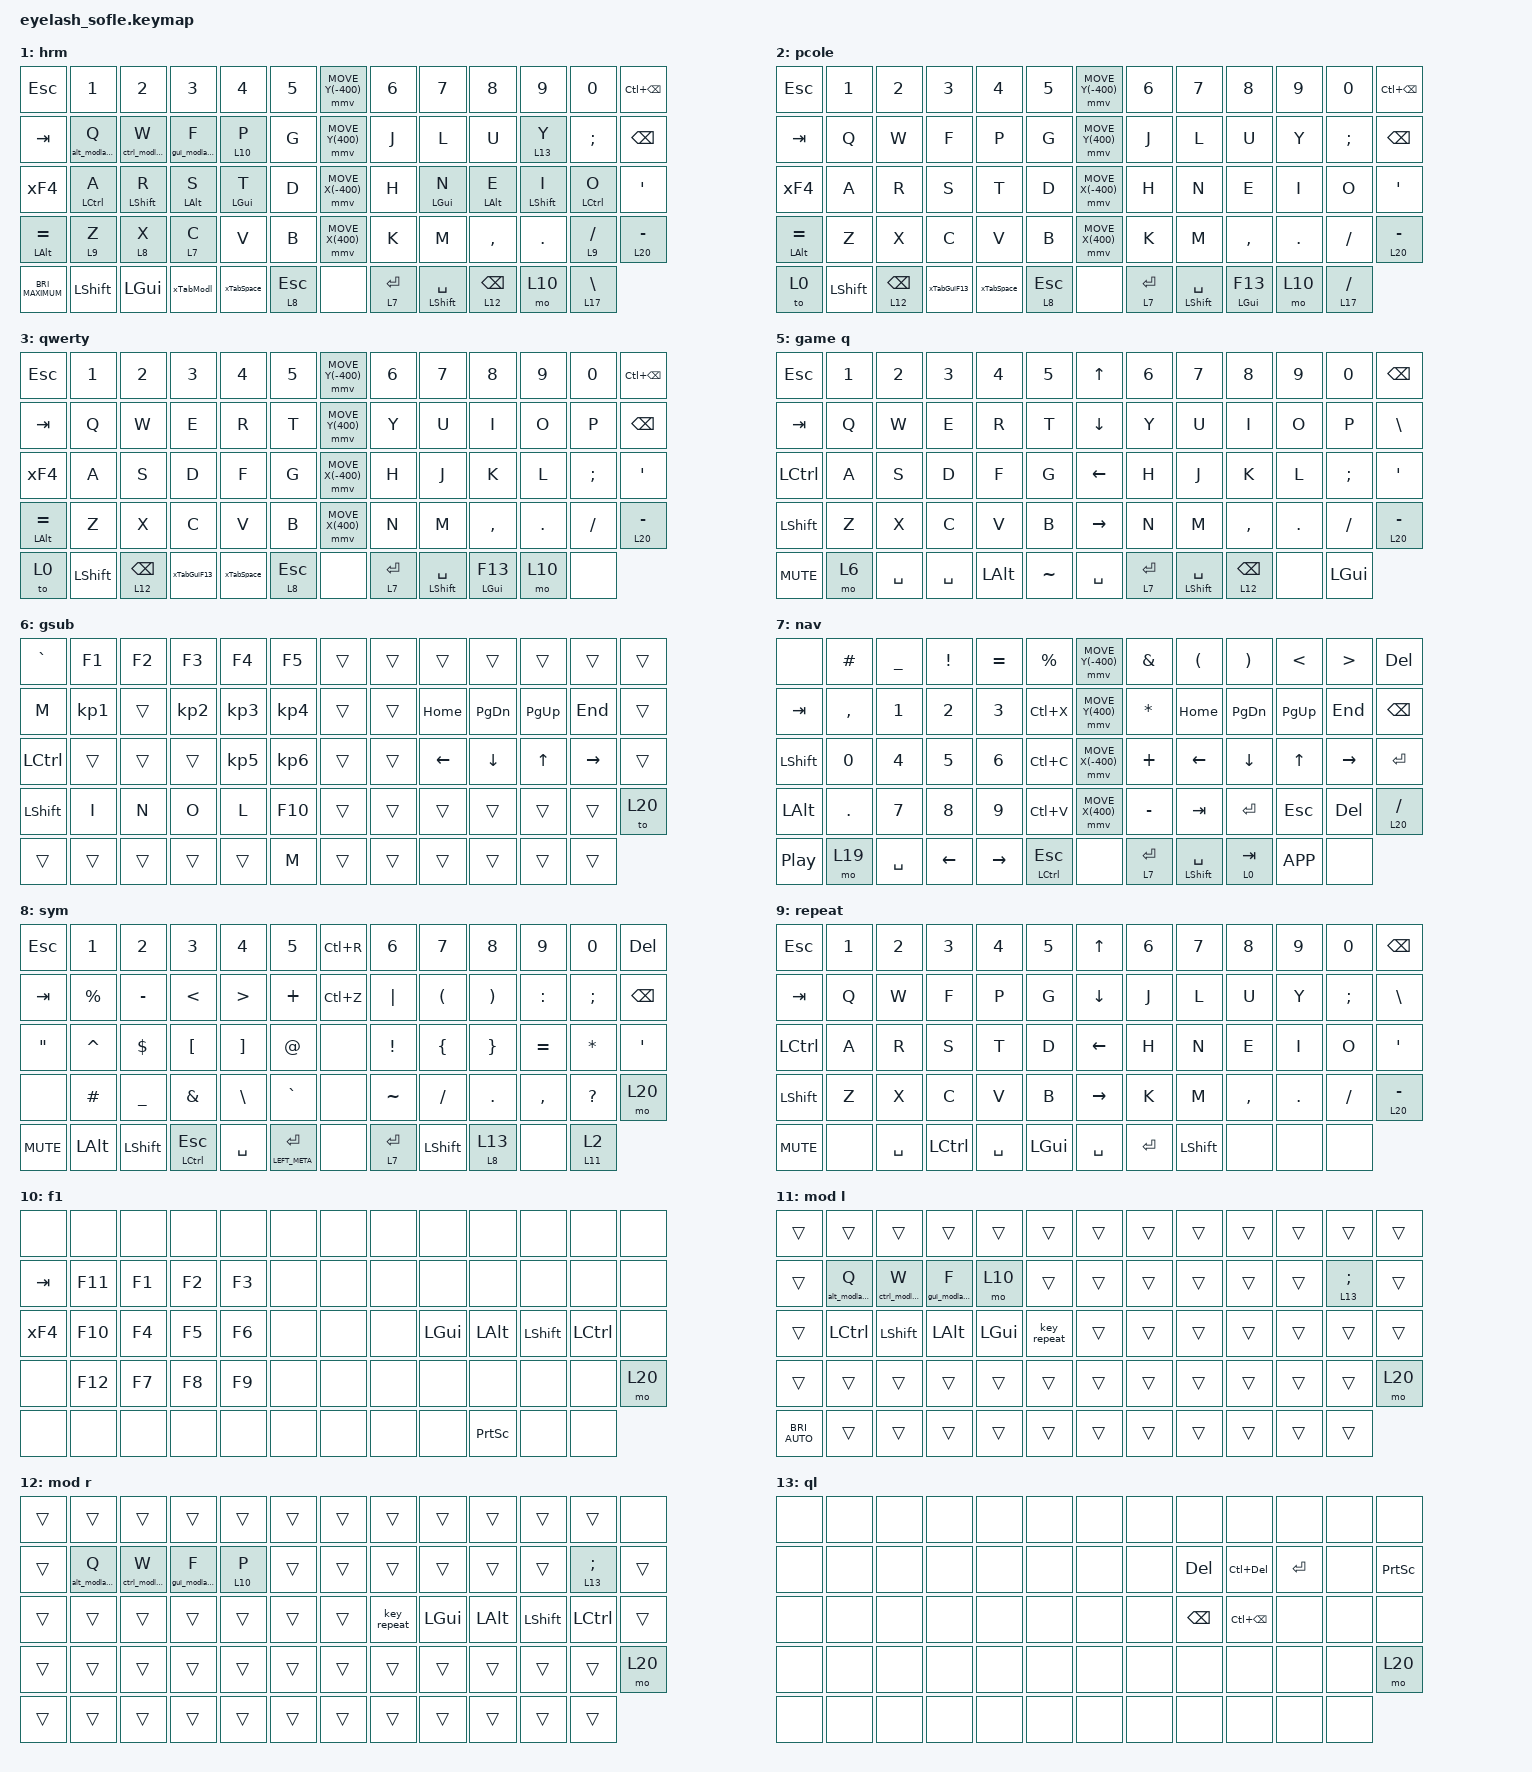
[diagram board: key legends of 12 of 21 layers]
#define ZMK_POINTING_DEFAULT_MOVE_VAL 1200  // 600
#define ZMK_POINTING_DEFAULT_SCRL_VAL 25   // 10

#include <input/processors.dtsi>
#include <zephyr/dt-bindings/input/input-event-codes.h>
#include <behaviors.dtsi>
#include <dt-bindings/zmk/backlight.h>
#include <dt-bindings/zmk/bt.h>
#include <dt-bindings/zmk/ext_power.h>
#include <dt-bindings/zmk/keys.h>
#include <dt-bindings/zmk/outputs.h>
#include <dt-bindings/zmk/pointing.h>
#include <dt-bindings/zmk/rgb.h>

&mmv_input_listener { input-processors = <&zip_xy_scaler 2 1>; };

&msc_input_listener { input-processors = <&zip_scroll_scaler 2 1>; };

&msc {
    acceleration-exponent = <1>;      // 0
    time-to-max-speed-ms = <100>;       // 300
    delay-ms = <0>;                   // 0
};

&mmv {
    time-to-max-speed-ms = <500>;
    acceleration-exponent = <1>;
    trigger-period-ms = <16>;
};

#define COMBO_SYM_SETTINGS_COMMON    \
    layers = <0 1 2 3>;    \
    timeout-ms = <15>;    \
    require-prior-idle-ms = <150>;
#define COMBO_MOD_SETTINGS_COMMON    \
    layers = <0 1 2 3>;    \
    timeout-ms = <15>;    \
    slow-release;    \
    require-prior-idle-ms = <150>;

/ {
    scroll_encoder: scroll_encoder {
        compatible = "zmk,behavior-sensor-rotate";
        #sensor-binding-cells = <0>;
        bindings = <&msc SCRL_DOWN>, <&msc SCRL_UP>;

        tap-ms = <100>;
    };

    // ------------------------------------------------------------------------------
    //				   conditions
    // ------------------------------------------------------------------------------
    // ------------------------------------------------------------------------------
    //				    testing
    // ------------------------------------------------------------------------------
    // ------------------------------------------------------------------------------
    //				   behaviors
    // ------------------------------------------------------------------------------

    zHomeMod: zHomeMod {
        compatible = "zmk,behavior-hold-tap";
        label = "ZHOMEMOD";
        bindings = <&kp>, <&kp>;

        #binding-cells = <2>;
        tapping-term-ms = <250>;
        quick-tap-ms = <200>;
        flavor = "tap-preferred";
        require-prior-idle-ms = <130>;
    };

    zHomeLayer: zHomeLayer {
        compatible = "zmk,behavior-hold-tap";
        label = "ZHOMELAYER";
        bindings = <&mo>, <&kp>;

        #binding-cells = <2>;
        tapping-term-ms = <250>;
        quick-tap-ms = <200>;
        flavor = "tap-preferred";
        require-prior-idle-ms = <130>;
    };

    xTab: xTab {
        compatible = "zmk,behavior-mod-morph";
        label = "XTAB";
        bindings = <&kp LEFT_WIN>, <&kp TAB>;

        #binding-cells = <0>;
        mods = <(MOD_LALT|MOD_RCTL)>;
        keep-mods = <(MOD_LALT)>;
    };

    xShiftonSpace: xShiftonSpace {
        compatible = "zmk,behavior-mod-morph";
        label = "XSHIFTONSPACE";
        bindings = <&kp SPACE>, <&zFast_Mod LEFT_SHIFT SPACE>;

        #binding-cells = <0>;
        mods = <(MOD_LCTL|MOD_LGUI|MOD_LALT)>;
        keep-mods = <(MOD_LCTL|MOD_LGUI|MOD_LALT)>;
    };

    xEntertab: xEntertab {
        compatible = "zmk,behavior-mod-morph";
        label = "XENTERTAB";
        bindings = <&zFast_Mod LGUI ENTER>, <&kp TAB>;

        #binding-cells = <0>;
        mods = <(MOD_LALT)>;
        keep-mods = <(MOD_LALT)>;
    };

    ySpacecap: ySpacecap {
        compatible = "zmk,behavior-tap-dance";
        label = "YSPACECAP";
        #binding-cells = <0>;
        bindings = <&kp SPACE>, <&caps_word>;

        tapping-term-ms = <200>;
    };

    yOutput: yOutput {
        compatible = "zmk,behavior-tap-dance";
        label = "YOUTPUT";
        #binding-cells = <0>;
        tapping-term-ms = <300>;
        bindings = <&out OUT_BLE>, <&out OUT_USB>;
    };

    zFastLayer: zFastLayer {
        compatible = "zmk,behavior-hold-tap";
        label = "ZFASTLAYER";
        bindings = <&mo>, <&kp>;

        #binding-cells = <2>;
        hold-while-undecided;
        tapping-term-ms = <200>;
    };

    xF4: xF4 {
        compatible = "zmk,behavior-mod-morph";
        label = "XF4";
        bindings = <&zFast_Mod LEFT_CONTROL BACKSLASH>, <&kp F4>;

        #binding-cells = <0>;
        mods = <(MOD_LALT)>;
        keep-mods = <(MOD_LALT)>;
    };

    yPower: yPower {
        compatible = "zmk,behavior-tap-dance";
        label = "YPOWER";
        #binding-cells = <0>;
        bindings = <&ext_power EP_ON>, <&ext_power EP_OFF>;

        tapping-term-ms = <300>;
    };

    yBtClear: yBtClear {
        compatible = "zmk,behavior-tap-dance";
        label = "YBTCLEAR";
        #binding-cells = <0>;
        tapping-term-ms = <300>;
        bindings = <&none>, <&none>, <&bt BT_CLR>;
    };

    zFast_Mod: zFast_Mod {
        compatible = "zmk,behavior-hold-tap";
        label = "ZFAST_MOD";
        bindings = <&kp>, <&kp>;

        #binding-cells = <2>;
        tapping-term-ms = <200>;
        hold-while-undecided;
    };

    yOff: yOff {
        compatible = "zmk,behavior-tap-dance";
        label = "YOFF";
        #binding-cells = <0>;
        bindings = <&kp LG(L)>, <&soft_off>;

        tapping-term-ms = <300>;
    };

    yBacklight: yBacklight {
        compatible = "zmk,behavior-tap-dance";
        label = "YBACKLIGHT";
        #binding-cells = <0>;
        bindings = <&bl BL_ON>, <&bl BL_OFF>;
    };

    yColour: yColour {
        compatible = "zmk,behavior-tap-dance";
        label = "YCOLOUR";
        #binding-cells = <0>;
        tapping-term-ms = <300>;
        bindings =
            <&rgb_ug RGB_COLOR_HSB(0,0,58)>,
            <&rgb_ug RGB_COLOR_HSB(269,87,84)>,
            <&rgb_ug RGB_COLOR_HSB(173,36,27)>;
    };

    stickylayer: stickylayer {
        compatible = "zmk,behavior-hold-tap";
        label = "STICKYLAYER";
        bindings = <&mo>, <&sl>;

        #binding-cells = <2>;
        tapping-term-ms = <150>;
        hold-while-undecided;
    };

    z2layer: z2layer {
        compatible = "zmk,behavior-hold-tap";
        label = "Z2LAYER";
        bindings = <&mo>, <&to>;

        #binding-cells = <2>;
        hold-while-undecided;
        tapping-term-ms = <200>;
    };

    zSlowLayer: zSlowLayer {
        compatible = "zmk,behavior-hold-tap";
        label = "ZSLOWLAYER";
        bindings = <&mo>, <&kp>;

        #binding-cells = <2>;
        tapping-term-ms = <180>;
        quick-tap-ms = <150>;
        flavor = "tap-preferred";
    };

    zHome_alt: zHome_alt {
        compatible = "zmk,behavior-hold-tap";
        label = "ZHOME_ALT";
        bindings = <&alt_modlayer>, <&kp>;

        #binding-cells = <2>;
        tapping-term-ms = <250>;
        quick-tap-ms = <200>;
        flavor = "tap-preferred";
        require-prior-idle-ms = <130>;
    };

    zHome_ctrl: zHome_ctrl {
        compatible = "zmk,behavior-hold-tap";
        label = "ZHOME_CTRL";
        bindings = <&ctrl_modlayer>, <&kp>;

        #binding-cells = <2>;
        tapping-term-ms = <250>;
        quick-tap-ms = <200>;
        flavor = "tap-preferred";
        require-prior-idle-ms = <130>;
    };

    zHome_gui: zHome_gui {
        compatible = "zmk,behavior-hold-tap";
        label = "ZHOME_GUI";
        bindings = <&gui_modlayer>, <&kp>;

        #binding-cells = <2>;
        tapping-term-ms = <250>;
        quick-tap-ms = <200>;
        flavor = "tap-preferred";
        require-prior-idle-ms = <130>;
    };

    bl_up: bl_up {
        compatible = "zmk,behavior-tap-dance";
        label = "Backlight Up";
        #binding-cells = <0>;
        bindings = <&bl BL_INC>, <&bl_on_max>;

        tapping-term-ms = <150>;
    };

    bl_down: bl_down {
        compatible = "zmk,behavior-tap-dance";
        label = "Backlight Down";
        #binding-cells = <0>;
        bindings = <&bl BL_DEC>, <&bl BL_SET 40>;

        tapping-term-ms = <150>;
    };

    bt_1: bt_1 {
        compatible = "zmk,behavior-tap-dance";
        label = "bt_1";
        #binding-cells = <0>;
        bindings = <&bt BT_SEL 1>, <&bt BT_DISC 1>;

        tapping-term-ms = <150>;
    };

    bt_0: bt_0 {
        compatible = "zmk,behavior-tap-dance";
        label = "BT_0";
        #binding-cells = <0>;
        bindings = <&bt BT_SEL 0>, <&bt BT_DISC 0>;

        tapping-term-ms = <150>;
    };

    bt_2: bt_2 {
        compatible = "zmk,behavior-tap-dance";
        label = "BT_2";
        #binding-cells = <0>;
        bindings = <&bt BT_SEL 2>, <&bt BT_DISC 2>;

        tapping-term-ms = <150>;
    };

    bt_3: bt_3 {
        compatible = "zmk,behavior-tap-dance";
        label = "BT_3";
        #binding-cells = <0>;
        bindings = <&bt BT_SEL 3>, <&bt BT_DISC 3>;

        tapping-term-ms = <150>;
    };

    bt_4: bt_4 {
        compatible = "zmk,behavior-tap-dance";
        label = "BT_4";
        #binding-cells = <0>;
        bindings = <&bt BT_SEL 4>, <&bt BT_DISC 4>;

        tapping-term-ms = <150>;
    };

    bt_5: bt_5 {
        compatible = "zmk,behavior-tap-dance";
        label = "BT_5";
        #binding-cells = <0>;
        bindings = <&bt BT_SEL 5>, <&bt BT_DISC 5>;

        tapping-term-ms = <150>;
    };

    zhomemod_r: zhomemod_r {
        compatible = "zmk,behavior-hold-tap";
        label = "ZHOMEMOD_R";
        bindings = <&kp>, <&kp>;

        #binding-cells = <2>;
        tapping-term-ms = <250>;
        quick-tap-ms = <200>;
        flavor = "tap-preferred";
        require-prior-idle-ms = <130>;
        hold-trigger-key-positions = <18 31 44 42 43 30 17 16 29 28 15 4 5 2 3 1 13 0 14 27 26 56 57 55 54 53 41 40 39 52 59 60 61 62 63 6 58 19 32 45>;
    };

    zhomemod_l: zhomemod_l {
        compatible = "zmk,behavior-hold-tap";
        label = "ZHOMEMOD_L";
        bindings = <&kp>, <&kp>;

        #binding-cells = <2>;
        tapping-term-ms = <250>;
        quick-tap-ms = <200>;
        flavor = "tap-preferred";
        require-prior-idle-ms = <130>;
        hold-trigger-key-positions = <57 56 52 19 58 32 45 6 59 60 61 63 11 20 21 22 23 24 33 34 35 36 37 46 47 48 49 50 60 61 62 63 7 8 9 10 11 12 20 21 22 23 24 25 33 34 35 36 37 38 46 47 48 49 50 51 60 61 62 63 53 54 55>;
    };

    zhomelayer_r: zhomelayer_r {
        compatible = "zmk,behavior-hold-tap";
        label = "ZHOMELAYER_R";
        bindings = <&mo>, <&kp>;

        #binding-cells = <2>;
        tapping-term-ms = <250>;
        quick-tap-ms = <200>;
        flavor = "tap-preferred";
        require-prior-idle-ms = <130>;
        hold-trigger-key-positions = <0 1 2 3 4 5 6 13 14 15 16 17 18 19 26 27 28 29 30 31 32 39 40 41 42 43 44 45 52 53 54 55 56 57 58 59 60 61 62 63>;
    };

    zhomelayer_l: zhomelayer_l {
        compatible = "zmk,behavior-hold-tap";
        label = "ZHOMELAYER_L";
        bindings = <&mo>, <&kp>;

        #binding-cells = <2>;
        tapping-term-ms = <250>;
        quick-tap-ms = <200>;
        flavor = "tap-preferred";
        require-prior-idle-ms = <130>;
        hold-trigger-key-positions = <6 7 8 9 10 11 12 19 20 21 22 23 24 25 32 33 34 35 36 37 38 45 46 47 48 49 50 51 52 58 61 62 63 53 54 55 56 57 59 60>;
    };

    xTabSpace: xTabSpace {
        compatible = "zmk,behavior-mod-morph";
        label = "XTABSPACE";
        bindings = <&kp SPACE>, <&kp TAB>;

        #binding-cells = <0>;
        mods = <(MOD_LALT|MOD_RCTL)>;
        keep-mods = <(MOD_LALT)>;
    };

    xTabModl: xTabModl {
        compatible = "zmk,behavior-mod-morph";
        label = "XTABMODL";
        bindings = <&zFastLayer 11 F13>, <&kp LS(TAB)>;

        #binding-cells = <0>;
        mods = <(MOD_LALT|MOD_RCTL)>;
        keep-mods = <(MOD_LALT)>;
    };

    xTabGuiF13: xTabGuiF13 {
        compatible = "zmk,behavior-mod-morph";
        label = "XTABGUIF13";
        bindings = <&zFast_Mod LEFT_GUI F13>, <&kp LS(TAB)>;

        #binding-cells = <0>;
        mods = <(MOD_LALT|MOD_RCTL)>;
        keep-mods = <(MOD_LALT)>;
    };

    yExt: yExt {
        compatible = "zmk,behavior-tap-dance";
        label = "YEXT";
        #binding-cells = <0>;
        bindings = <&ext_power EP_ON>, <&ext_power EP_OFF>;
    };

    // ------------------------------------------------------------------------------
    //				     combos
    // ------------------------------------------------------------------------------

    combos {
        compatible = "zmk,combos";

        paren_open {
            COMBO_SYM_SETTINGS_COMMON
            bindings = <&kp LEFT_PARENTHESIS>;
            key-positions = <21 22>;
        };

        paren_close {
            COMBO_SYM_SETTINGS_COMMON
            bindings = <&kp RIGHT_PARENTHESIS>;
            key-positions = <23 22>;
        };

        quote_all {
            COMBO_SYM_SETTINGS_COMMON
            bindings = <&kp DOUBLE_QUOTES>;
            key-positions = <21 23>;
        };

        brace_left {
            COMBO_SYM_SETTINGS_COMMON
            bindings = <&kp LEFT_BRACE>;
            key-positions = <34 35>;
        };

        brace_right {
            COMBO_SYM_SETTINGS_COMMON
            bindings = <&kp RIGHT_BRACE>;
            key-positions = <36 35>;
        };

        equal {
            COMBO_SYM_SETTINGS_COMMON
            bindings = <&kp EQUAL>;
            key-positions = <43 42>;
        };

        at {
            COMBO_SYM_SETTINGS_COMMON
            bindings = <&kp AT_SIGN>;
            key-positions = <47 49>;
        };

        meta {
            COMBO_MOD_SETTINGS_COMMON
            bindings = <&kp LEFT_GUI>;
            key-positions = <20 21>;
        };

        meta2 {
            COMBO_MOD_SETTINGS_COMMON
            bindings = <&kp LEFT_GUI>;
            key-positions = <18 17>;
        };

        hash {
            COMBO_SYM_SETTINGS_COMMON
            bindings = <&kp HASH>;
            key-positions = <34 35 36 49>;
        };

        percentage {
            COMBO_SYM_SETTINGS_COMMON
            bindings = <&kp PERCENT>;
            key-positions = <39 47 48 49>;
        };

        dollar {
            COMBO_SYM_SETTINGS_COMMON
            bindings = <&kp DOLLAR>;
            key-positions = <34 36>;
        };

        star {
            COMBO_SYM_SETTINGS_COMMON
            bindings = <&kp STAR>;
            key-positions = <30 28>;
        };

        plus {
            COMBO_SYM_SETTINGS_COMMON
            bindings = <&kp PLUS>;
            key-positions = <15 17>;
        };

        minus {
            COMBO_SYM_SETTINGS_COMMON
            bindings = <&kp MINUS>;
            key-positions = <32 41 42>;
        };

        divide {
            COMBO_SYM_SETTINGS_COMMON
            bindings = <&kp SLASH>;
            key-positions = <30 31>;
        };

        greater {
            COMBO_SYM_SETTINGS_COMMON
            bindings = <&kp GREATER_THAN>;
            key-positions = <16 17>;
        };

        less {
            COMBO_SYM_SETTINGS_COMMON
            bindings = <&kp LESS_THAN>;
            key-positions = <16 15>;
        };

        bracket_close {
            COMBO_SYM_SETTINGS_COMMON
            bindings = <&kp RIGHT_BRACKET>;
            key-positions = <30 29>;
        };

        bracket_open {
            COMBO_SYM_SETTINGS_COMMON
            bindings = <&kp LEFT_BRACKET>;
            key-positions = <29 28>;
        };

        and {
            COMBO_SYM_SETTINGS_COMMON
            bindings = <&kp AMPERSAND>;
            key-positions = <37 36>;
        };

        caret {
            COMBO_SYM_SETTINGS_COMMON
            bindings = <&kp CARET>;
            key-positions = <14 15>;
        };

        tilde {
            COMBO_SYM_SETTINGS_COMMON
            bindings = <&kp TILDE>;
            key-positions = <27 28>;
        };

        shift {
            COMBO_MOD_SETTINGS_COMMON
            bindings = <&kp LEFT_SHIFT>;
            key-positions = <33 34>;
        };

        shift2 {
            COMBO_MOD_SETTINGS_COMMON
            bindings = <&kp LEFT_SHIFT>;
            key-positions = <30 31>;
        };

        alt2 {
            COMBO_MOD_SETTINGS_COMMON
            bindings = <&kp LEFT_ALT>;
            key-positions = <46 47>;
        };

        alt {
            COMBO_MOD_SETTINGS_COMMON
            bindings = <&kp LEFT_ALT>;
            key-positions = <44 43>;
        };

        slash {
            COMBO_SYM_SETTINGS_COMMON
            bindings = <&kp BACKSLASH>;
            key-positions = <47 48>;
        };
    };

    // ------------------------------------------------------------------------------
    //				     macros
    // ------------------------------------------------------------------------------

    macros {
        alt_modlayer: alt_modlayer {
            compatible = "zmk,behavior-macro";
            wait-ms = <0>;
            tap-ms = <0>;
            #binding-cells = <0>;
            bindings =
                <&macro_press>,
                <&mo 14>,
                <&macro_press>,
                <&kp LALT>,
                <&macro_pause_for_release>,
                <&macro_release>,
                <&kp LALT>,
                <&macro_release>,
                <&mo 14>;
        };

        ctrl_modlayer: ctrl_modlayer {
            compatible = "zmk,behavior-macro";
            wait-ms = <0>;
            tap-ms = <0>;
            #binding-cells = <0>;
            bindings =
                <&macro_press>,
                <&mo 15>,
                <&macro_press>,
                <&kp LEFT_CONTROL>,
                <&macro_pause_for_release>,
                <&macro_release>,
                <&kp LEFT_CONTROL>,
                <&macro_release>,
                <&mo 15>;

            label = "CTRL_MODLAYER";
        };

        gui_modlayer: gui_modlayer {
            compatible = "zmk,behavior-macro";
            wait-ms = <0>;
            tap-ms = <0>;
            #binding-cells = <0>;
            bindings =
                <&macro_press>,
                <&mo 16>,
                <&macro_press>,
                <&kp LEFT_GUI>,
                <&macro_pause_for_release>,
                <&macro_release>,
                <&kp LEFT_GUI>,
                <&macro_release>,
                <&mo 16>;

            label = "GUI_MODLAYER";
        };

        bl_on_max: bl_setting {
            compatible = "zmk,behavior-macro";
            #binding-cells = <0>;
            bindings = <&bl BL_ON &bl BL_SET 100>;
            label = "BL_SETTING";
        };
    };

    behaviors {
    };

    // ------------------------------------------------------------------------------
    //				    keymaps
    // ------------------------------------------------------------------------------

    keymap {
        compatible = "zmk,keymap";

        l_cole {
            display-name = "cole";
            bindings = <
&kp ESCAPE                 &kp N1          &kp N2        &kp N3     &kp N4      &kp N5                  &zFastLayer 17 PRINTSCREEN     &kp N6               &kp N7                       &kp N8                    &kp N9   &kp N0                    &kp BACKSPACE
&kp TAB                    &kp Q           &kp W         &kp F      &kp P       &kp G                   &zFastLayer 7 LS(LC(LA(F14)))  &kp J                &kp L                        &kp U                     &kp Y    &kp SEMI                  &kp BSLH
&xF4                       &kp A           &kp R         &kp S      &kp T       &kp D                   &zFastLayer 18 LS(TAB)         &kp H                &kp N                        &kp E                     &kp I    &kp O                     &kp APOS
&zFast_Mod LEFT_ALT EQUAL  &kp Z           &kp X         &kp C      &kp V       &kp B                   &kp TAB                        &kp K                &kp M                        &kp COMMA                 &kp DOT  &kp FSLH                  &zFastLayer 20 MINUS
&kp C_MUTE                 &kp LEFT_SHIFT  &kp LEFT_GUI  &xTabModl  &xTabSpace  &zFastLayer 8 ESCAPE    &none                          &zFastLayer 7 ENTER  &zFast_Mod LEFT_SHIFT SPACE  &zFastLayer 12 BACKSPACE  &mo 10   &zFastLayer 17 BACKSLASH
            >;

            //sensor-bindings = <&scroll_morph>;

            sensor-bindings = <&inc_dec_kp C_VOLUME_UP C_VOLUME_DOWN>;
        };

        l_hrm {
            display-name = "hrm";
            bindings = <
&kp ESCAPE                 &kp N1                      &kp N2                    &kp N3                  &kp N4                  &kp N5                  &mmv MOVE_Y(-400)  &kp N6               &kp N7                       &kp N8                    &kp N9                    &kp N0                      &kp LC(BACKSPACE)
&kp TAB                    &zHome_alt 0 Q              &zHome_ctrl 0 W           &zHome_gui 0 F          &zHomeLayer 10 P        &kp G                   &mmv MOVE_Y(400)   &kp J                &kp L                        &kp U                     &zHomeLayer 13 Y          &kp SEMI                    &kp BACKSPACE
&xF4                       &zhomemod_l LEFT_CONTROL A  &zhomemod_l LEFT_SHIFT R  &zhomemod_l LEFT_ALT S  &zhomemod_l LEFT_GUI T  &kp D                   &mmv MOVE_X(-400)  &kp H                &zhomemod_r LEFT_GUI N       &zhomemod_r LEFT_ALT E    &zhomemod_r LEFT_SHIFT I  &zhomemod_r LEFT_CONTROL O  &kp APOS
&zFast_Mod LEFT_ALT EQUAL  &zHomeLayer 9 Z             &zhomelayer_l 8 X         &zhomelayer_l 7 C       &kp V                   &kp B                   &mmv MOVE_X(400)   &kp K                &kp M                        &kp COMMA                 &kp DOT                   &zHomeLayer 9 SLASH         &zFastLayer 20 MINUS
&kp C_BRIGHTNESS_MAXIMUM   &kp LEFT_SHIFT              &kp LEFT_GUI              &xTabModl               &xTabSpace              &zFastLayer 8 ESCAPE    &none              &zFastLayer 7 ENTER  &zFast_Mod LEFT_SHIFT SPACE  &zFastLayer 12 BACKSPACE  &mo 10                    &zFastLayer 17 BACKSLASH
            >;

            sensor-bindings = <&inc_dec_kp C_BRIGHTNESS_INC C_BRIGHTNESS_DEC>;
        };

        l_pcole {
            display-name = "pcole";
            bindings = <
&kp ESCAPE                 &kp N1          &kp N2                    &kp N3       &kp N4      &kp N5                  &mmv MOVE_Y(-400)  &kp N6               &kp N7                       &kp N8                   &kp N9   &kp N0                &kp LC(BACKSPACE)
&kp TAB                    &kp Q           &kp W                     &kp F        &kp P       &kp G                   &mmv MOVE_Y(400)   &kp J                &kp L                        &kp U                    &kp Y    &kp SEMI              &kp BACKSPACE
&xF4                       &kp A           &kp R                     &kp S        &kp T       &kp D                   &mmv MOVE_X(-400)  &kp H                &kp N                        &kp E                    &kp I    &kp O                 &kp APOS
&zFast_Mod LEFT_ALT EQUAL  &kp Z           &kp X                     &kp C        &kp V       &kp B                   &mmv MOVE_X(400)   &kp K                &kp M                        &kp COMMA                &kp DOT  &kp FSLH              &zFastLayer 20 MINUS
&to 0                      &kp LEFT_SHIFT  &zFastLayer 12 BACKSPACE  &xTabGuiF13  &xTabSpace  &zFastLayer 8 ESCAPE    &none              &zFastLayer 7 ENTER  &zFast_Mod LEFT_SHIFT SPACE  &zFast_Mod LEFT_GUI F13  &mo 10   &zFastLayer 17 SLASH
            >;

            sensor-bindings = <&inc_dec_kp A B>;
        };

        l_qwerty {
            display-name = "qwerty";
            bindings = <
&kp ESCAPE                 &kp N1          &kp N2                    &kp N3       &kp N4      &kp N5                  &mmv MOVE_Y(-400)  &kp N6               &kp N7                       &kp N8                   &kp N9   &kp N0    &kp LC(BACKSPACE)
&kp TAB                    &kp Q           &kp W                     &kp E        &kp R       &kp T                   &mmv MOVE_Y(400)   &kp Y                &kp U                        &kp I                    &kp O    &kp P     &kp BACKSPACE
&xF4                       &kp A           &kp S                     &kp D        &kp F       &kp G                   &mmv MOVE_X(-400)  &kp H                &kp J                        &kp K                    &kp L    &kp SEMI  &kp APOS
&zFast_Mod LEFT_ALT EQUAL  &kp Z           &kp X                     &kp C        &kp V       &kp B                   &mmv MOVE_X(400)   &kp N                &kp M                        &kp COMMA                &kp DOT  &kp FSLH  &zFastLayer 20 MINUS
&to 0                      &kp LEFT_SHIFT  &zFastLayer 12 BACKSPACE  &xTabGuiF13  &xTabSpace  &zFastLayer 8 ESCAPE    &none              &zFastLayer 7 ENTER  &zFast_Mod LEFT_SHIFT SPACE  &zFast_Mod LEFT_GUI F13  &mo 10   &none
            >;

            sensor-bindings = <&inc_dec_kp A B>;
        };

        l_game {
            display-name = "game";
            bindings = <
&kp ESCAPE        &kp N1  &kp N2          &kp N3     &kp N4        &kp N5                  &zFastLayer 17 PRINTSCREEN     &kp N6               &kp N7                       &kp N8                    &kp N9   &kp N0        &kp BSPC
&kp TAB           &kp Q   &kp W           &kp F      &kp P         &kp G                   &zFastLayer 7 LS(LA(LC(F14)))  &kp J                &kp L                        &kp U                     &kp Y    &kp SEMI      &kp BSLH
&kp LEFT_CONTROL  &kp A   &kp R           &kp S      &kp T         &kp D                   &kp LEFT                       &kp H                &kp N                        &kp E                     &kp I    &kp O         &kp SQT
&kp LSHFT         &kp Z   &kp X           &kp C      &kp V         &kp B                   &kp LG(RS(S))                  &kp K                &kp M                        &kp COMMA                 &kp DOT  &kp FSLH      &zFastLayer 20 MINUS
&kp C_MUTE        &mo 6   &kp LEFT_SHIFT  &kp SPACE  &kp LEFT_ALT  &zFastLayer 7 ESCAPE    &kp SPACE                      &zFastLayer 8 ENTER  &zFast_Mod LEFT_SHIFT SPACE  &zFastLayer 12 BACKSPACE  &none    &kp LEFT_GUI
            >;

            sensor-bindings = <&inc_dec_kp UP_ARROW DOWN_ARROW>;
        };

        l_gameq {
            display-name = "game q";
            bindings = <
&kp ESCAPE        &kp N1  &kp N2     &kp N3     &kp N4        &kp N5       &kp UP     &kp N6               &kp N7                       &kp N8                    &kp N9   &kp N0        &kp BSPC
&kp TAB           &kp Q   &kp W      &kp E      &kp R         &kp T        &kp DOWN   &kp Y                &kp U                        &kp I                     &kp O    &kp P         &kp BSLH
&kp LEFT_CONTROL  &kp A   &kp S      &kp D      &kp F         &kp G        &kp LEFT   &kp H                &kp J                        &kp K                     &kp L    &kp SEMI      &kp SQT
&kp LSHFT         &kp Z   &kp X      &kp C      &kp V         &kp B        &kp RIGHT  &kp N                &kp M                        &kp COMMA                 &kp DOT  &kp FSLH      &zFastLayer 20 MINUS
&kp C_MUTE        &mo 6   &kp SPACE  &kp SPACE  &kp LEFT_ALT  &kp TILDE    &kp SPACE  &zFastLayer 7 ENTER  &zFast_Mod LEFT_SHIFT SPACE  &zFastLayer 12 BACKSPACE  &none    &kp LEFT_GUI
            >;

            sensor-bindings = <&inc_dec_kp C_VOLUME_UP C_VOLUME_DOWN>;
        };

        l_gsub {
            display-name = "gsub";
            bindings = <
&kp GRAVE  &kp F1           &kp F2  &kp F3           &kp F4           &kp F5             &trans  &trans  &trans    &trans     &trans     &trans     &trans
&kp M      &kp KP_NUMBER_1  &trans  &kp KP_NUMBER_2  &kp KP_NUMBER_3  &kp KP_NUMBER_4    &trans  &trans  &kp HOME  &kp PG_DN  &kp PG_UP  &kp END    &trans
&kp LCTRL  &trans           &trans  &trans           &kp KP_NUMBER_5  &kp KP_NUMBER_6    &trans  &trans  &kp LEFT  &kp DOWN   &kp UP     &kp RIGHT  &trans
&kp LSHFT  &kp I            &kp N   &kp O            &kp L            &kp F10            &trans  &trans  &trans    &trans     &trans     &trans     &to 20
&trans     &trans           &trans  &trans           &trans           &kp M              &trans  &trans  &trans    &trans     &trans     &trans
            >;
        };

        layer_nav {
            display-name = "nav";
            bindings = <
&none             &kp HASH   &kp UNDERSCORE  &kp EXCLAMATION  &kp EQUAL        &kp PERCENT                       &mmv MOVE_Y(-400)  &kp AMPERSAND        &kp LEFT_PARENTHESIS        &kp RIGHT_PARENTHESIS  &kp LESS_THAN  &kp GREATER_THAN  &kp DELETE
&kp TAB           &kp COMMA  &kp N1          &kp N2           &kp N3           &kp LC(X)                         &mmv MOVE_Y(400)   &kp ASTERISK         &kp HOME                    &kp PG_DN              &kp PG_UP      &kp END           &kp BACKSPACE
&kp LEFT_SHIFT    &kp N0     &kp N4          &kp N5           &kp N6           &kp LC(C)                         &mmv MOVE_X(-400)  &kp PLUS             &kp LEFT                    &kp DOWN               &kp UP         &kp RIGHT         &kp RET
&kp LALT          &kp DOT    &kp N7          &kp N8           &kp N9           &kp LC(V)                         &mmv MOVE_X(400)   &kp MINUS            &kp TAB                     &kp ENTER              &kp ESCAPE     &kp DELETE        &zFastLayer 20 SLASH
&kp C_PLAY_PAUSE  &mo 19     &kp SPACE       &kp LEFT_ARROW   &kp RIGHT_ARROW  &zFast_Mod LEFT_CONTROL ESCAPE    &none              &zFastLayer 7 ENTER  &zHomeMod LEFT_SHIFT SPACE  &zFastLayer 0 TAB      &kp K_APP      &none
            >;

            sensor-bindings = <&inc_dec_kp UP_ARROW DOWN_ARROW>;
        };

        layer_sym {
            display-name = "sym";
            bindings = <
&kp ESCAPE         &kp N1        &kp N2          &kp N3                          &kp N4             &kp N5                        &kp LC(R)  &kp N6               &kp N7                &kp N8                 &kp N9     &kp N0         &kp DELETE
&kp TAB            &kp PERCENT   &kp MINUS       &kp LESS_THAN                   &kp GREATER_THAN   &kp PLUS                      &kp LC(Z)  &kp PIPE             &kp LEFT_PARENTHESIS  &kp RIGHT_PARENTHESIS  &kp COLON  &kp SEMICOLON  &kp BSPC
&kp DOUBLE_QUOTES  &kp CARET     &kp DOLLAR      &kp LEFT_BRACKET                &kp RIGHT_BRACKET  &kp AT_SIGN                   &none      &kp EXCLAMATION      &kp LEFT_BRACE        &kp RIGHT_BRACE        &kp EQUAL  &kp ASTERISK   &kp SINGLE_QUOTE
&none              &kp HASH      &kp UNDERSCORE  &kp AMPERSAND                   &kp BACKSLASH      &kp GRAVE                     &none      &kp TILDE            &kp SLASH             &kp PERIOD             &kp COMMA  &kp QUESTION   &mo 20
&kp C_MUTE         &kp LEFT_ALT  &kp LEFT_SHIFT  &zFast_Mod LEFT_CONTROL ESCAPE  &kp SPACE          &zFast_Mod LEFT_META ENTER    &none      &zFastLayer 7 ENTER  &kp LEFT_SHIFT        &stickylayer 8 13      &none      &z2layer 11 2
            >;

            sensor-bindings = <&inc_dec_kp C_VOLUME_UP C_VOLUME_DOWN>;
        };

        l_repeat {
            display-name = "repeat";
            bindings = <
&kp ESCAPE        &kp N1  &kp N2     &kp N3            &kp N4     &kp N5          &kp UP     &kp N6     &kp N7          &kp N8     &kp N9   &kp N0    &kp BSPC
&kp TAB           &kp Q   &kp W      &kp F             &kp P      &kp G           &kp DOWN   &kp J      &kp L           &kp U      &kp Y    &kp SEMI  &kp BSLH
&kp LEFT_CONTROL  &kp A   &kp R      &kp S             &kp T      &kp D           &kp LEFT   &kp H      &kp N           &kp E      &kp I    &kp O     &kp SQT
&kp LSHFT         &kp Z   &kp X      &kp C             &kp V      &kp B           &kp RIGHT  &kp K      &kp M           &kp COMMA  &kp DOT  &kp FSLH  &zFastLayer 20 MINUS
&kp C_MUTE        &none   &kp SPACE  &kp LEFT_CONTROL  &kp SPACE  &kp LEFT_GUI    &kp SPACE  &kp ENTER  &kp LEFT_SHIFT  &none      &none    &none
            >;

            sensor-bindings = <&inc_dec_kp C_VOLUME_UP C_VOLUME_DOWN>;
        };

        l_f1 {
            display-name = "f1";
            bindings = <
&none    &none    &none   &none   &none   &none    &none  &none  &none     &none            &none      &none      &none
&kp TAB  &kp F11  &kp F1  &kp F2  &kp F3  &none    &none  &none  &none     &none            &none      &none      &none
&xF4     &kp F10  &kp F4  &kp F5  &kp F6  &none    &none  &none  &kp LGUI  &kp LALT         &kp LSHFT  &kp LCTRL  &none
&none    &kp F12  &kp F7  &kp F8  &kp F9  &none    &none  &none  &none     &none            &none      &none      &mo 20
&none    &none    &none   &none   &none   &none    &none  &none  &none     &kp PRINTSCREEN  &none      &none
            >;
        };

        l_modl {
            display-name = "mod l";
            bindings = <
&trans                 &trans          &trans           &trans          &trans    &trans         &trans  &trans  &trans  &trans  &trans  &trans                    &trans
&trans                 &zHome_alt 0 Q  &zHome_ctrl 0 W  &zHome_gui 0 F  &mo 10    &trans         &trans  &trans  &trans  &trans  &trans  &zFastLayer 13 SEMICOLON  &trans
&trans                 &kp LCTRL       &kp LSHFT        &kp LALT        &kp LGUI  &key_repeat    &trans  &trans  &trans  &trans  &trans  &trans                    &trans
&trans                 &trans          &trans           &trans          &trans    &trans         &trans  &trans  &trans  &trans  &trans  &trans                    &mo 20
&kp C_BRIGHTNESS_AUTO  &trans          &trans           &trans          &trans    &trans         &trans  &trans  &trans  &trans  &trans  &trans
            >;

            sensor-bindings = <&inc_dec_kp C_BRIGHTNESS_INC C_BRIGHTNESS_DEC>;
        };

        l_modr {
            display-name = "mod r";
            bindings = <
&trans  &trans          &trans           &trans          &trans            &trans    &trans  &trans       &trans    &trans    &trans     &trans                    &none
&trans  &zHome_alt 0 Q  &zHome_ctrl 0 W  &zHome_gui 0 F  &zHomeLayer 10 P  &trans    &trans  &trans       &trans    &trans    &trans     &zFastLayer 13 SEMICOLON  &trans
&trans  &trans          &trans           &trans          &trans            &trans    &trans  &key_repeat  &kp LGUI  &kp LALT  &kp LSHFT  &kp LCTRL                 &trans
&trans  &trans          &trans           &trans          &trans            &trans    &trans  &trans       &trans    &trans    &trans     &trans                    &mo 20
&trans  &trans          &trans           &trans          &trans            &trans    &trans  &trans       &trans    &trans    &trans     &trans
            >;

            sensor-bindings = <&inc_dec_kp TAB LS(TAB)>;
        };

        layer_ql {
            display-name = "ql";
            bindings = <
&none  &none  &none  &none  &none  &none    &none  &none  &none     &none         &none    &none  &none
&none  &none  &none  &none  &none  &none    &none  &none  &kp DEL   &kp LC(DEL)   &kp RET  &none  &kp PRINTSCREEN
&none  &none  &none  &none  &none  &none    &none  &none  &kp BSPC  &kp LC(BSPC)  &none    &none  &none
&none  &none  &none  &none  &none  &none    &none  &none  &none     &none         &none    &none  &mo 20
&none  &none  &none  &none  &none  &none    &none  &none  &none     &none         &none    &none
            >;
        };

        l_alt {
            display-name = "alt";
            bindings = <
&none  &none  &none      &none        &none      &none      &none  &none      &none     &none      &none      &none      &none
&none  &none  &kp LCTRL  &none        &kp D      &kp F4     &none  &kp P      &kp HOME  &kp PG_DN  &kp PG_UP  &kp END    &none
&none  &none  &kp LSHFT  &kp LS(TAB)  &kp TAB    &none      &none  &none      &kp LEFT  &kp DOWN   &kp UP     &kp RIGHT  &none
&none  &none  &none      &none        &none      &none      &none  &none      &none     &none      &none      &none      &mo 20
&none  &none  &none      &kp ESC      &kp SPACE  &kp RET    &none  &kp ENTER  &none     &none      &none      &none
            >;
        };

        l_ctrl {
            display-name = "ctrl";
            bindings = <
&none           &none           &none  &none        &none      &none      &none  &none      &none     &none      &none      &none      &none
&kp LS(ESCAPE)  &kp LEFT_SHIFT  &none  &kp Z        &kp Y      &kp Q      &none  &kp T      &kp HOME  &kp PG_DN  &kp PG_UP  &kp END    &kp PRINTSCREEN
&kp LA(DEL)     &kp A           &none  &kp LS(TAB)  &kp TAB    &kp W      &none  &kp BSPC   &kp LEFT  &kp DOWN   &kp UP     &kp RIGHT  &none
&none           &none           &none  &kp P        &kp LS(N)  &kp N      &kp N  &none      &kp C     &kp V      &kp X      &kp A      &mo 20
&none           &none           &none  &kp ESC      &kp SPACE  &kp RET    &none  &kp ENTER  &none     &none      &none      &none
            >;
        };

        l_gui {
            display-name = "gui";
            bindings = <
&none        &none        &none      &none    &none      &none      &none  &none      &none      &none      &none      &none       &none
&kp ESC      &kp LCTRL    &kp LSHFT  &none    &kp E      &kp R      &none  &kp Q      &kp HOME   &kp PG_DN  &kp PG_UP  &kp END     &kp PRINTSCREEN
&kp LA(DOT)  &kp LS(TAB)  &kp LS(S)  &none    &kp TAB    &kp W      &none  &kp PLUS   &kp LEFT   &kp DOWN   &kp RIGHT  &kp UP      &kp PAUSE_BREAK
&kp X        &kp P        &kp LC(D)  &kp M    &kp D      &kp L      &none  &kp MINUS  &kp R      &kp V      &none      &kp LC(N4)  &mo 20
&none        &none        &none      &kp ESC  &kp SPACE  &kp RET    &none  &kp RET    &kp LSHFT  &none      &none      &none
            >;
        };

        l_func {
            display-name = "func";
            bindings = <
&kp ESCAPE  &none      &none      &none     &kp PAUSE_BREAK  &kp PRINTSCREEN    &none  &kp C_AL_FILES                     &kp C_MEDIA_GAMES  &kp C_AC_BACK  &kp C_AC_HOME  &kp C_AC_BOOKMARKS  &kp C_PIP
&none       &none      &none      &none     &none            &none              &none  &kp C_AC_DESKTOP_SHOW_ALL_WINDOWS  &kp HOME           &kp PG_DN      &kp PG_UP      &kp END             &kp PRINTSCREEN
&none       &kp LCTRL  &kp LSHFT  &kp LALT  &kp LGUI         &none              &none  &kp C_AL_TASK_MANAGER              &kp LGUI           &kp LALT       &kp LSHFT      &kp LCTRL           &none
&none       &none      &none      &none     &none            &none              &none  &kp C_AL_TEXT_EDITOR               &kp C_AL_WWW       &none          &none          &none               &mo 20
&none       &none      &none      &none     &none            &none              &none  &none                              &none              &none          &none          &none
            >;

            sensor-bindings = <&inc_dec_kp C_BRIGHTNESS_INC C_BRIGHTNESS_DEC>;
        };

        l_media {
            display-name = "media";
            bindings = <
&none  &none         &none       &none       &none               &none               &kp UP     &none             &none      &none     &none   &none      &none
&none  &none         &none       &none       &none               &kp C_MUTE          &kp DOWN   &none             &kp P      &kp N     &none   &none      &none
&none  &kp C_REWIND  &kp C_PREV  &kp C_NEXT  &kp C_FAST_FORWARD  &kp C_PLAY_PAUSE    &kp LEFT   &none             &kp LEFT   &kp DOWN  &kp UP  &kp RIGHT  &none
&none  &kp LEFT      &kp DOWN    &kp RIGHT   &kp UP              &none               &kp RIGHT  &none             &none      &none     &none   &none      &mo 20
&none  &none         &none       &kp LCTRL   &kp SPACE           &kp C_PLAY_PAUSE    &kp RET    &kp LEFT_CONTROL  &kp SPACE  &none     &none   &none
            >;
        };

        l_mouse {
            display-name = "mouse";
            bindings = <
&none    &none      &none      &none       &none          &none    &none  &none  &none           &none           &none         &none            &none
&kp TAB  &none      &mkp MCLK  &mkp RCLK   &mkp LCLK      &kp X    &none  &none  &kp HOME        &kp PG_DN       &kp PG_UP     &kp END          &kp BACKSPACE
&none    &kp LCTRL  &kp LSHFT  &kp LALT    &kp LGUI       &kp C    &none  &none  &mmv MOVE_LEFT  &mmv MOVE_DOWN  &mmv MOVE_UP  &mmv MOVE_RIGHT  &kp ENTER
&none    &none      &none      &kp K_BACK  &kp K_FORWARD  &kp V    &none  &none  &msc SCRL_LEFT  &msc SCRL_DOWN  &msc SCRL_UP  &msc SCRL_RIGHT  &mo 20
&none    &none      &none      &none       &none          &none    &none  &none  &none           &none           &none         &none
            >;
        };

        layer_fn {
            display-name = "fn";
            bindings = <
&bt_0            &none  &none  &none  &none   &bt_4       &rgb_ug RGB_SAI  &bl BL_INC            &bl BL_DEC            &none   &none  &none          &bt BT_CLR
&bt_1            &none  &to 4  &to 5  &none   &bt_5       &rgb_ug RGB_SAD  &yExt                 &kp A                 &none   &none  &none          &none
&bt_2            &to 0  &to 1  &to 2  &to 0   &none       &rgb_ug RGB_BRD  &yBacklight           &none                 &none   &none  &none          &to 0
&bt_3            &none  &none  &none  &to 19  &yOutput    &rgb_ug RGB_BRI  &kp C_BRIGHTNESS_INC  &kp C_BRIGHTNESS_DEC  &none   &none  &none          &to 20
&rgb_ug RGB_TOG  &none  &none  &none  &none   &none       &yColour         &none                 &none                 &to 18  &none  &z2layer 11 2
            >;

            sensor-bindings = <&inc_dec_kp C_VOLUME_UP C_VOLUME_DOWN>;
        };
    };

    conditional_layers { compatible = "zmk,conditional-layers"; };
};
